# ioat91sam7s64 register map
Registers are 32-bit, access not given, no defined reset value unless marked. A register's access mark holds for its fields unless they carry their own. Addresses are absolute; registers are grouped by the start of their names; [hi:lo] are bit positions; 'fields as' and 'values as' point back to an identical list.

## US1
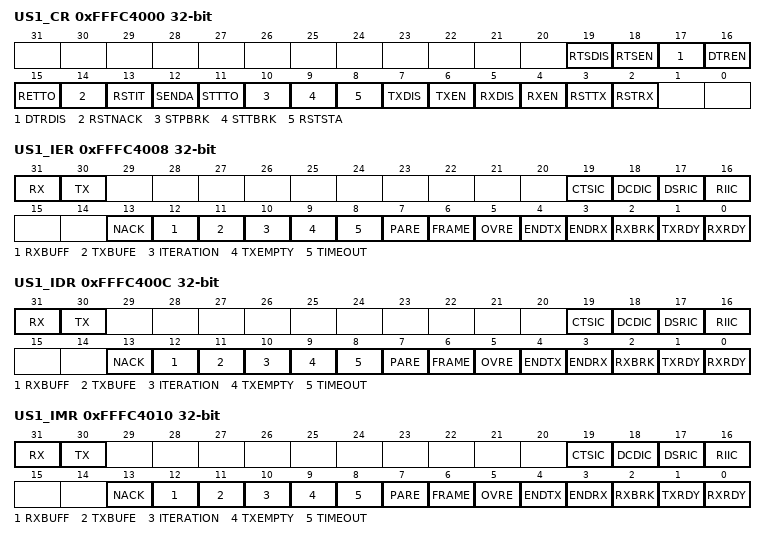
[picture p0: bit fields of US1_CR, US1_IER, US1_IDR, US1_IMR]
0xFFFC4000 US1_CR
  [19] RTSDIS, [18] RTSEN, [17] DTRDIS, [16] DTREN, [15] RETTO, [14] RSTNACK, [13] RSTIT, [12] SENDA, [11] STTTO, [10] STPBRK, [9] STTBRK, [8] RSTSTA, [7] TXDIS, [6] TXEN, [5] RXDIS, [4] RXEN, [3] RSTTX, [2] RSTRX
0xFFFC4004 US1_MR
  [28] FILTER, [24] ITER, [21] DSNACK, [20] INACK, [19] OVER, [18] CKLO, [17] MODE9, [16] MSBF, [16:14] CHMODE, [14:12] NBSTOP, [12:9] PAR, [8] SYNC, [8:6] CHRL, [6:4] CLKS, [4:0] USMODE
0xFFFC4008 US1_IER
  [31] RX, [30] TX, [19] CTSIC, [18] DCDIC, [17] DSRIC, [16] RIIC, [13] NACK, [12] RXBUFF, [11] TXBUFE, [10] ITERATION, [9] TXEMPTY, [8] TIMEOUT, [7] PARE, [6] FRAME, [5] OVRE, [4] ENDTX, [3] ENDRX, [2] RXBRK, [1] TXRDY, [0] RXRDY
0xFFFC400C US1_IDR
  fields as US1_IER
0xFFFC4010 US1_IMR
  fields as US1_IER
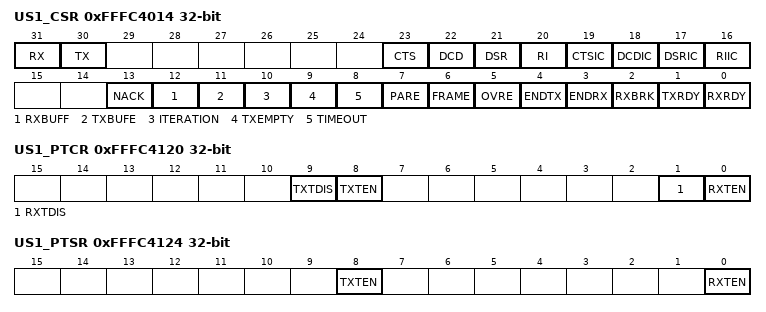
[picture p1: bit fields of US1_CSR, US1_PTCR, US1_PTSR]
0xFFFC4014 US1_CSR
  [31] RX, [30] TX, [23] CTS, [22] DCD, [21] DSR, [20] RI, [19] CTSIC, [18] DCDIC, [17] DSRIC, [16] RIIC, [13] NACK, [12] RXBUFF, [11] TXBUFE, [10] ITERATION, [9] TXEMPTY, [8] TIMEOUT, [7] PARE, [6] FRAME, [5] OVRE, [4] ENDTX, [3] ENDRX, [2] RXBRK, [1] TXRDY, [0] RXRDY
0xFFFC4018 US1_RHR
0xFFFC401C US1_THR
0xFFFC4020 US1_BRGR
0xFFFC4024 US1_RTOR
0xFFFC4028 US1_TTGR
0xFFFC4040 US1_FIDI
0xFFFC4044 US1_NER
0xFFFC4048 US1_XXR
0xFFFC404C US1_IF
0xFFFC4100 US1_RPR
0xFFFC4104 US1_RCR
0xFFFC4108 US1_TPR
0xFFFC410C US1_TCR
0xFFFC4110 US1_RNPR
0xFFFC4114 US1_RNCR
0xFFFC4118 US1_TNPR
0xFFFC411C US1_TNCR
0xFFFC4120 US1_PTCR
  [9] TXTDIS, [8] TXTEN, [1] RXTDIS, [0] RXTEN
0xFFFC4124 US1_PTSR
  [8] TXTEN, [0] RXTEN

## US0
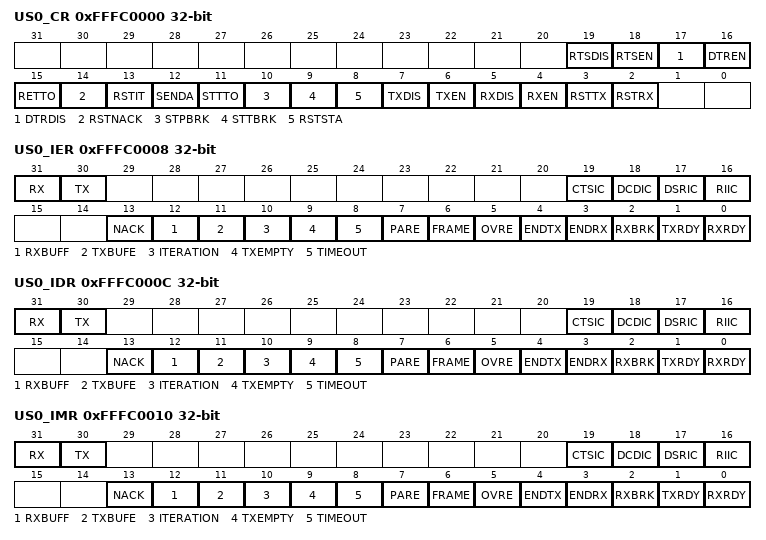
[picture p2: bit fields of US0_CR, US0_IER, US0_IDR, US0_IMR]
0xFFFC0000 US0_CR
  [19] RTSDIS, [18] RTSEN, [17] DTRDIS, [16] DTREN, [15] RETTO, [14] RSTNACK, [13] RSTIT, [12] SENDA, [11] STTTO, [10] STPBRK, [9] STTBRK, [8] RSTSTA, [7] TXDIS, [6] TXEN, [5] RXDIS, [4] RXEN, [3] RSTTX, [2] RSTRX
0xFFFC0004 US0_MR
  [28] FILTER, [24] ITER, [21] DSNACK, [20] INACK, [19] OVER, [18] CKLO, [17] MODE9, [16] MSBF, [16:14] CHMODE, [14:12] NBSTOP, [12:9] PAR, [8] SYNC, [8:6] CHRL, [6:4] CLKS, [4:0] USMODE
0xFFFC0008 US0_IER
  [31] RX, [30] TX, [19] CTSIC, [18] DCDIC, [17] DSRIC, [16] RIIC, [13] NACK, [12] RXBUFF, [11] TXBUFE, [10] ITERATION, [9] TXEMPTY, [8] TIMEOUT, [7] PARE, [6] FRAME, [5] OVRE, [4] ENDTX, [3] ENDRX, [2] RXBRK, [1] TXRDY, [0] RXRDY
0xFFFC000C US0_IDR
  fields as US0_IER
0xFFFC0010 US0_IMR
  fields as US0_IER
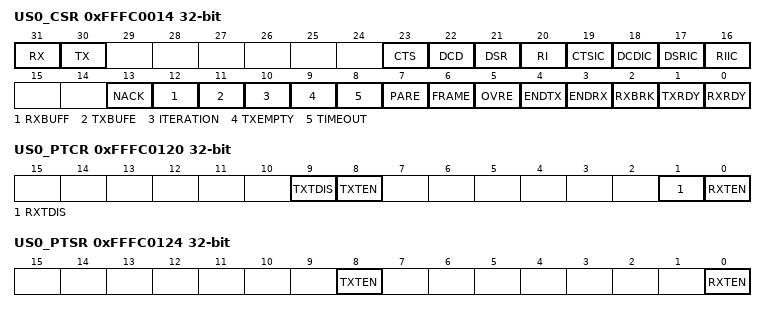
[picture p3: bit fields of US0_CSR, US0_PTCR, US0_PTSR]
0xFFFC0014 US0_CSR
  [31] RX, [30] TX, [23] CTS, [22] DCD, [21] DSR, [20] RI, [19] CTSIC, [18] DCDIC, [17] DSRIC, [16] RIIC, [13] NACK, [12] RXBUFF, [11] TXBUFE, [10] ITERATION, [9] TXEMPTY, [8] TIMEOUT, [7] PARE, [6] FRAME, [5] OVRE, [4] ENDTX, [3] ENDRX, [2] RXBRK, [1] TXRDY, [0] RXRDY
0xFFFC0018 US0_RHR
0xFFFC001C US0_THR
0xFFFC0020 US0_BRGR
0xFFFC0024 US0_RTOR
0xFFFC0028 US0_TTGR
0xFFFC0040 US0_FIDI
0xFFFC0044 US0_NER
0xFFFC0048 US0_XXR
0xFFFC004C US0_IF
0xFFFC0100 US0_RPR
0xFFFC0104 US0_RCR
0xFFFC0108 US0_TPR
0xFFFC010C US0_TCR
0xFFFC0110 US0_RNPR
0xFFFC0114 US0_RNCR
0xFFFC0118 US0_TNPR
0xFFFC011C US0_TNCR
0xFFFC0120 US0_PTCR
  [9] TXTDIS, [8] TXTEN, [1] RXTDIS, [0] RXTEN
0xFFFC0124 US0_PTSR
  [8] TXTEN, [0] RXTEN

## TWI
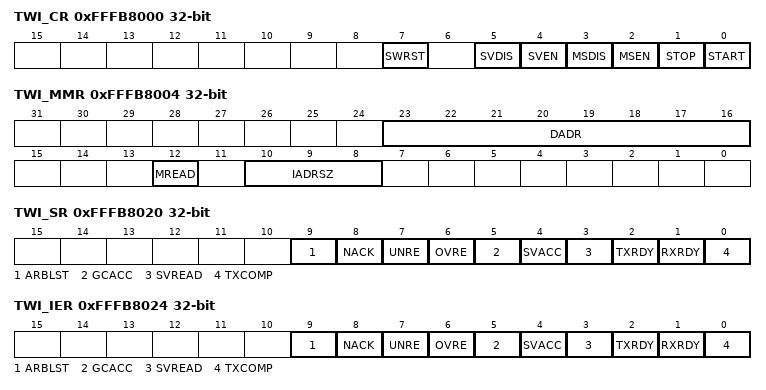
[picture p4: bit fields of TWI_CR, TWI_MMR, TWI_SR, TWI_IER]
0xFFFB8000 TWI_CR
  [7] SWRST, [5] SVDIS, [4] SVEN, [3] MSDIS, [2] MSEN, [1] STOP, [0] START
0xFFFB8004 TWI_MMR
  [23:16] DADR, [12] MREAD, [10:8] IADRSZ
0xFFFB8008 TWI_SMR
  [23:16] SADR
0xFFFB800C TWI_IADR
0xFFFB8010 TWI_CWGR
  [19:16] CKDIV, [16:8] CHDIV, [8:0] CLDIV
0xFFFB8020 TWI_SR
  [9] ARBLST, [8] NACK, [7] UNRE, [6] OVRE, [5] GCACC, [4] SVACC, [3] SVREAD, [2] TXRDY, [1] RXRDY, [0] TXCOMP
0xFFFB8024 TWI_IER
  fields as TWI_SR
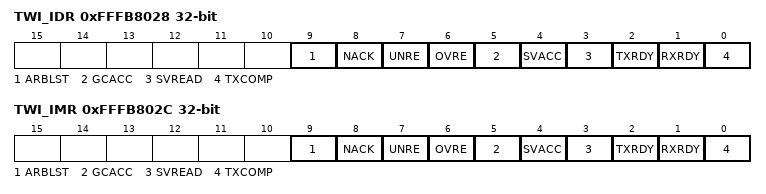
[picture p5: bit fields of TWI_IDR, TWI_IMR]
0xFFFB8028 TWI_IDR
  fields as TWI_SR
0xFFFB802C TWI_IMR
  fields as TWI_SR
0xFFFB8030 TWI_RHR
0xFFFB8034 TWI_THR

## TC2
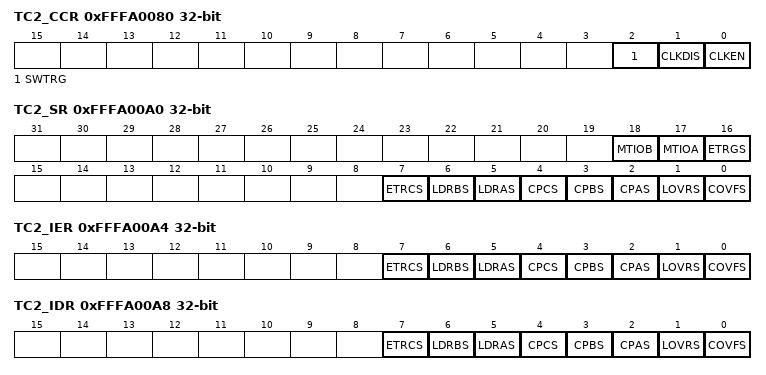
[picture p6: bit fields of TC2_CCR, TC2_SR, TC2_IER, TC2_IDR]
0xFFFA0080 TC2_CCR
  [2] SWTRG, [1] CLKDIS, [0] CLKEN
0xFFFA0084 TC2_CMR 40-bit
  [32:30] BSWTRG, [30:28] BEEVT, [28:26] BCPC, [26:24] BCPB, [24:22] ASWTRG, [22:20] AEEVT, [20:18] LDRB, [20:18] ACPC, [18:16] LDRA, [18:16] ACPA, [15] WAVE, [14] CPCTRG, [15:13] WAVESEL, [12] ENETRG, [10] ABETRG, [12:10] EEVT, [10:8] ETRGEDG, [10:8] EEVTEDG, [7] LDBDIS, [7] CPCDIS, [6] CPCSTOP, [6] LDBSTOP, [6:4] BURST, [3] CLKI, [3:0] CLKS
0xFFFA0090 TC2_CV
0xFFFA0094 TC2_RA
0xFFFA0098 TC2_RB
0xFFFA009C TC2_RC
0xFFFA00A0 TC2_SR
  [18] MTIOB, [17] MTIOA, [16] ETRGS, [7] ETRCS, [6] LDRBS, [5] LDRAS, [4] CPCS, [3] CPBS, [2] CPAS, [1] LOVRS, [0] COVFS
0xFFFA00A4 TC2_IER
  [7] ETRCS, [6] LDRBS, [5] LDRAS, [4] CPCS, [3] CPBS, [2] CPAS, [1] LOVRS, [0] COVFS
0xFFFA00A8 TC2_IDR
  fields as TC2_IER
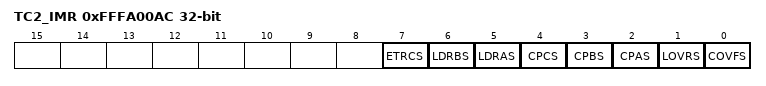
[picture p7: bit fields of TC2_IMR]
0xFFFA00AC TC2_IMR
  fields as TC2_IER
